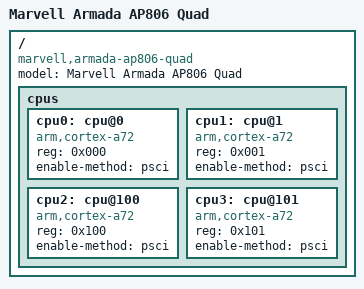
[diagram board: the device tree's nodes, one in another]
// SPDX-License-Identifier: (GPL-2.0+ OR MIT)
/*
 * Copyright (C) 2016 Marvell Technology Group Ltd.
 *
 * Device Tree file for Marvell Armada AP806.
 */

#include "armada-ap806.dtsi"

/ {
	model = "Marvell Armada AP806 Quad";
	compatible = "marvell,armada-ap806-quad", "marvell,armada-ap806";

	cpus {
		#address-cells = <1>;
		#size-cells = <0>;

		cpu0: cpu@0 {
			device_type = "cpu";
			compatible = "arm,cortex-a72", "arm,armv8";
			reg = <0x000>;
			enable-method = "psci";
		};
		cpu1: cpu@1 {
			device_type = "cpu";
			compatible = "arm,cortex-a72", "arm,armv8";
			reg = <0x001>;
			enable-method = "psci";
		};
		cpu2: cpu@100 {
			device_type = "cpu";
			compatible = "arm,cortex-a72", "arm,armv8";
			reg = <0x100>;
			enable-method = "psci";
		};
		cpu3: cpu@101 {
			device_type = "cpu";
			compatible = "arm,cortex-a72", "arm,armv8";
			reg = <0x101>;
			enable-method = "psci";
		};
	};
};
